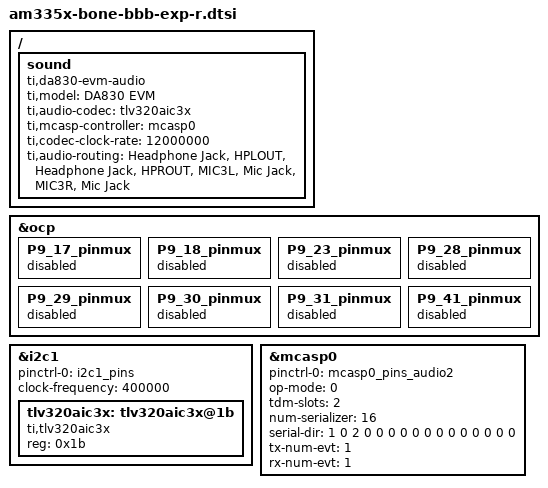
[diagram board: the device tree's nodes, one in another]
/*
 * Copyright (C) 2012 Texas Instruments Incorporated - http://www.ti.com/
 *
 * This program is free software; you can redistribute it and/or modify
 * it under the terms of the GNU General Public License version 2 as
 * published by the Free Software Foundation.
 */

#include "am335x-bone-can0.dtsi"
#include "am335x-bone-ttyO1.dtsi"
#include "am335x-bone-ttyO2.dtsi"
#include "am335x-bone-ttyO4.dtsi"

&ocp {
	/* i2c */
	P9_17_pinmux {
		status = "disabled";
	};
	P9_18_pinmux {
		status = "disabled";
	};
	/* edt-ft5306 irq pin */
	P9_23_pinmux {
		status = "disabled";
	};
	/* audio */
	P9_28_pinmux {
		status = "disabled";
	};
	P9_29_pinmux {
		status = "disabled";
	};
	P9_30_pinmux {
		status = "disabled";
	};
	P9_31_pinmux {
		status = "disabled";
	};
	P9_41_pinmux {
		status = "disabled";
	};
};

&i2c1 {
	pinctrl-names = "default";
	pinctrl-0 = <&i2c1_pins>;

	status = "okay";
	clock-frequency = <400000>;

	tlv320aic3x: tlv320aic3x@1b {
		compatible = "ti,tlv320aic3x";
		reg = <0x1b>;
		status = "okay";
	};
};

&mcasp0 {
	pinctrl-names = "default";
	pinctrl-0 = <&mcasp0_pins_audio2>;

	status = "okay";

	op-mode = <0>;          /* MCASP_IIS_MODE */
	tdm-slots = <2>;
	num-serializer = <16>;
	serial-dir = <  /* 0: INACTIVE, 1: TX, 2: RX */
		1 0 2 0
		0 0 0 0
		0 0 0 0
		0 0 0 0
	>;
	tx-num-evt = <1>;
	rx-num-evt = <1>;
};

/ {
	sound {
		compatible = "ti,da830-evm-audio";
		ti,model = "DA830 EVM";
		ti,audio-codec = <&tlv320aic3x>;
		ti,mcasp-controller = <&mcasp0>;
		ti,codec-clock-rate = <12000000>;
		ti,audio-routing =
			"Headphone Jack",       "HPLOUT",
			"Headphone Jack",       "HPROUT",
			"MIC3L",                "Mic Jack",
			"MIC3R",                "Mic Jack";
	};
};

/* Led */
/* #include "am335x-bone-led-gpio1-18.dtsi" */
/* #include "am335x-bone-led-gpio1-28.dtsi" */
/* #include "am335x-bone-led-gpio3-19.dtsi" */
#include "am335x-bone-led-gpio2-4-gpio2-5.dtsi"

/* Keypad */
/* #include "am335x-bone-keymap0.dtsi" */
/* #include "am335x-bone-keymap1.dtsi" */
/* #include "am335x-bone-keymap2.dtsi" */
#include "am335x-bone-keymap3.dtsi"

/* Backlight */
#include "am335x-bone-bl-gpio1-18.dtsi"

/* Touchscreen */
#include "am335x-bone-ti-tscadc-4-wire.dtsi"

/* Panel */
/* #include "am335x-bone-panel-320x240.dtsi" */
/* #include "am335x-bone-panel-480x272.dtsi" */
/* #include "am335x-bone-panel-800x480.dtsi" */
#include "am335x-bone-panel-1024x600-24bit.dtsi"
